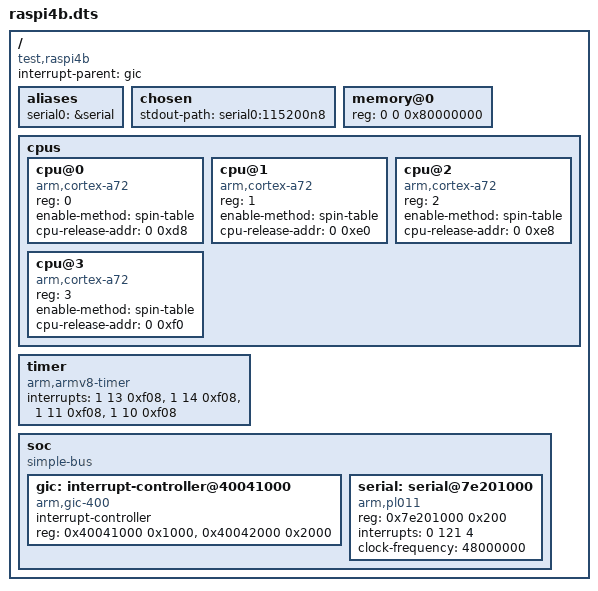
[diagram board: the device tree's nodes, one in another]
/dts-v1/;
/memreserve/ 0 0x100000;

// Minimal QEMU raspi4b test description, NOT a board build input or a
// replacement for physical-board firmware's complete device tree.
/ {
    #address-cells = <2>;
    #size-cells = <1>;
    compatible = "test,raspi4b";
    interrupt-parent = <&gic>;
    aliases { serial0 = &serial; };
    chosen { stdout-path = "serial0:115200n8"; };
    memory@0 { device_type = "memory"; reg = <0 0 0x80000000>; };
    cpus {
        #address-cells = <1>;
        #size-cells = <0>;
        cpu@0 { device_type = "cpu"; compatible = "arm,cortex-a72"; reg = <0>;
                enable-method = "spin-table"; cpu-release-addr = <0 0xd8>; };
        cpu@1 { device_type = "cpu"; compatible = "arm,cortex-a72"; reg = <1>;
                enable-method = "spin-table"; cpu-release-addr = <0 0xe0>; };
        cpu@2 { device_type = "cpu"; compatible = "arm,cortex-a72"; reg = <2>;
                enable-method = "spin-table"; cpu-release-addr = <0 0xe8>; };
        cpu@3 { device_type = "cpu"; compatible = "arm,cortex-a72"; reg = <3>;
                enable-method = "spin-table"; cpu-release-addr = <0 0xf0>; };
    };
    timer {
        compatible = "arm,armv8-timer";
        interrupts = <1 13 0xf08>, <1 14 0xf08>, <1 11 0xf08>, <1 10 0xf08>;
    };
    soc {
        compatible = "simple-bus";
        #address-cells = <1>;
        #size-cells = <1>;
        ranges = <0x7e000000 0 0xfe000000 0x01800000>,
                 <0x40000000 0 0xff800000 0x00800000>;
        gic: interrupt-controller@40041000 {
            compatible = "arm,gic-400";
            #address-cells = <0>;
            #interrupt-cells = <3>;
            interrupt-controller;
            reg = <0x40041000 0x1000>, <0x40042000 0x2000>;
        };
        serial: serial@7e201000 {
            compatible = "arm,pl011";
            reg = <0x7e201000 0x200>;
            interrupts = <0 121 4>;
            clock-frequency = <48000000>;
        };
    };
};
